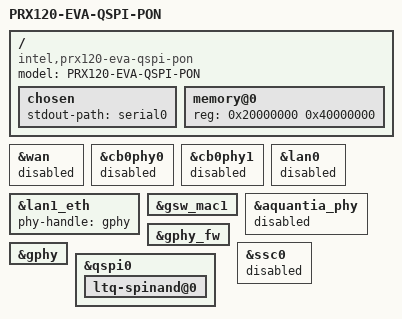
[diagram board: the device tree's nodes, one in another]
/dts-v1/;
#include "prx321-eva.dtsi"
#include "prx300-pon.dtsi"

/ {
	model = "PRX120-EVA-QSPI-PON";
	compatible = "intel,prx120-eva-qspi-pon", "intel,prx120-eva", "intel,prx300";

	chosen {
		stdout-path = "serial0";
	};

	memory@0 {
		device_type = "memory";
		reg = <0x20000000 0x40000000>; /* 1024 MB */
	};
};

&wan {
	status = "disabled";
};

&cb0phy0 {
	status = "disabled";
};

&cb0phy1 {
	status = "disabled";
};

&lan0 {
	status = "disabled";
};

&lan1_eth {
	phy-handle = <&gphy>;
};

&gsw_mac1 {
	/delete-property/ reset-gpios;
};

&aquantia_phy {
	status = "disabled";
};

&gphy_fw {
	status = "okay";
};

&gphy {
	status = "okay";
};

&ssc0 {
	status = "disabled";
};

&qspi0 {
	status = "okay";
	ltq-spinand@0 {
		status = "okay";
	};
};
